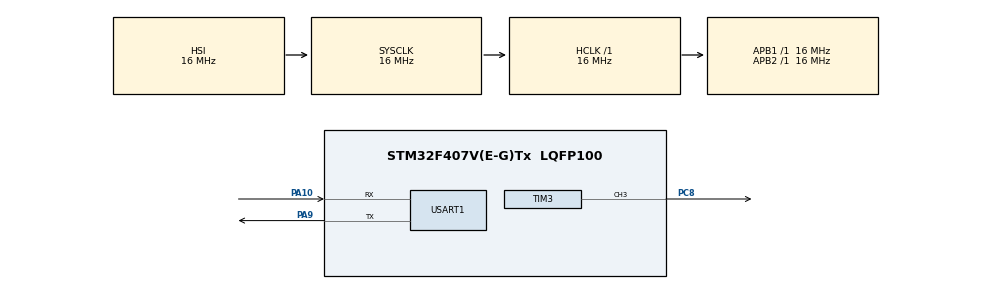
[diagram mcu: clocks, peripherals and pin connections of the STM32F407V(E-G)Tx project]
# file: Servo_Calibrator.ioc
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Mcu.Family=STM32F4
Mcu.Name=STM32F407V(E-G)Tx
Mcu.Package=LQFP100
NVIC.PriorityGroup=NVIC_PRIORITYGROUP_4
NVIC.USART1_IRQn=true\:0\:0\:false\:false\:true\:true\:true\:true
PA10.Mode=Asynchronous
PA10.Signal=USART1_RX
PA9.Mode=Asynchronous
PA9.Signal=USART1_TX
PC8.Signal=S_TIM3_CH3
ProjectManager.HeapSize=0x200
ProjectManager.StackSize=0x400
ProjectManager.TargetToolchain=STM32CubeIDE
RCC.AHBFreq_Value=16000000
RCC.APB1Freq_Value=16000000
RCC.APB2Freq_Value=16000000
RCC.CortexFreq_Value=16000000
RCC.HSE_VALUE=25000000
RCC.HSI_VALUE=16000000
RCC.LSE_VALUE=32768
RCC.SYSCLKFreq_VALUE=16000000
RCC.VCOOutputFreq_Value=192000000
SH.S_TIM3_CH3.0=TIM3_CH3,PWM Generation3 CH3
TIM3.Channel-PWM\ Generation3\ CH3=TIM_CHANNEL_3
TIM3.Period=19999
TIM3.Prescaler=15
USART1.VirtualMode=VM_ASYNC
board=custom

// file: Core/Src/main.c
/* USER CODE BEGIN Header */
/**
  ******************************************************************************
  * @file           : main.c
  * @brief          : Main program body
  ******************************************************************************
  * @attention
  *
  * Copyright (c) 2026 STMicroelectronics.
  * All rights reserved.
  *
  * This software is licensed under terms that can be found in the LICENSE file
  * in the root directory of this software component.
  * If no LICENSE file comes with this software, it is provided AS-IS.
  *
  ******************************************************************************
  */
/* USER CODE END Header */
#include "main.h"

TIM_HandleTypeDef htim3;

UART_HandleTypeDef huart1;

/* USER CODE BEGIN PV */
uint8_t rx_buffer[5];
/* USER CODE END PV */

void SystemClock_Config(void);
static void MX_GPIO_Init(void);
static void MX_TIM3_Init(void);
static void MX_USART1_UART_Init(void);

int main(void)
{

  /* MCU Configuration--------------------------------------------------------*/

  /* Reset of all peripherals, Initializes the Flash interface and the Systick. */
  HAL_Init();

  /* Configure the system clock */
  SystemClock_Config();

  /* Initialize all configured peripherals */
  MX_GPIO_Init();
  MX_TIM3_Init();
  MX_USART1_UART_Init();
  /* USER CODE BEGIN 2 */
  // Iniciar el PWM en el pin PC8
    HAL_TIM_PWM_Start(&htim3, TIM_CHANNEL_3);
    __HAL_TIM_SET_COMPARE(&htim3, TIM_CHANNEL_3, 1500); // Centro por defecto

    // Escuchar 5 bytes
    HAL_UART_Receive_IT(&huart1, rx_buffer, 5);
  /* USER CODE END 2 */

  /* Infinite loop */
  while (1)
  {

  }
}

void SystemClock_Config(void)
{
  RCC_OscInitTypeDef RCC_OscInitStruct = {0};
  RCC_ClkInitTypeDef RCC_ClkInitStruct = {0};

  /** Configure the main internal regulator output voltage
  */
  __HAL_RCC_PWR_CLK_ENABLE();
  __HAL_PWR_VOLTAGESCALING_CONFIG(PWR_REGULATOR_VOLTAGE_SCALE1);

  /** Initializes the RCC Oscillators according to the specified parameters
  * in the RCC_OscInitTypeDef structure.
  */
  RCC_OscInitStruct.OscillatorType = RCC_OSCILLATORTYPE_HSI;
  RCC_OscInitStruct.HSIState = RCC_HSI_ON;
  RCC_OscInitStruct.HSICalibrationValue = RCC_HSICALIBRATION_DEFAULT;
  RCC_OscInitStruct.PLL.PLLState = RCC_PLL_NONE;
  if (HAL_RCC_OscConfig(&RCC_OscInitStruct) != HAL_OK)
  {
    Error_Handler();
  }

  /** Initializes the CPU, AHB and APB buses clocks
  */
  RCC_ClkInitStruct.ClockType = RCC_CLOCKTYPE_HCLK|RCC_CLOCKTYPE_SYSCLK
                              |RCC_CLOCKTYPE_PCLK1|RCC_CLOCKTYPE_PCLK2;
  RCC_ClkInitStruct.SYSCLKSource = RCC_SYSCLKSOURCE_HSI;
  RCC_ClkInitStruct.AHBCLKDivider = RCC_SYSCLK_DIV1;
  RCC_ClkInitStruct.APB1CLKDivider = RCC_HCLK_DIV1;
  RCC_ClkInitStruct.APB2CLKDivider = RCC_HCLK_DIV1;

  if (HAL_RCC_ClockConfig(&RCC_ClkInitStruct, FLASH_LATENCY_0) != HAL_OK)
  {
    Error_Handler();
  }
}

static void MX_TIM3_Init(void)
{

  TIM_MasterConfigTypeDef sMasterConfig = {0};
  TIM_OC_InitTypeDef sConfigOC = {0};

  htim3.Instance = TIM3;
  htim3.Init.Prescaler = 15;
  htim3.Init.CounterMode = TIM_COUNTERMODE_UP;
  htim3.Init.Period = 19999;
  htim3.Init.ClockDivision = TIM_CLOCKDIVISION_DIV1;
  htim3.Init.AutoReloadPreload = TIM_AUTORELOAD_PRELOAD_DISABLE;
  if (HAL_TIM_PWM_Init(&htim3) != HAL_OK)
  {
    Error_Handler();
  }
  sMasterConfig.MasterOutputTrigger = TIM_TRGO_RESET;
  sMasterConfig.MasterSlaveMode = TIM_MASTERSLAVEMODE_DISABLE;
  if (HAL_TIMEx_MasterConfigSynchronization(&htim3, &sMasterConfig) != HAL_OK)
  {
    Error_Handler();
  }
  sConfigOC.OCMode = TIM_OCMODE_PWM1;
  sConfigOC.Pulse = 0;
  sConfigOC.OCPolarity = TIM_OCPOLARITY_HIGH;
  sConfigOC.OCFastMode = TIM_OCFAST_DISABLE;
  if (HAL_TIM_PWM_ConfigChannel(&htim3, &sConfigOC, TIM_CHANNEL_3) != HAL_OK)
  {
    Error_Handler();
  }
  HAL_TIM_MspPostInit(&htim3);

}

static void MX_USART1_UART_Init(void)
{

  huart1.Instance = USART1;
  huart1.Init.BaudRate = 115200;
  huart1.Init.WordLength = UART_WORDLENGTH_8B;
  huart1.Init.StopBits = UART_STOPBITS_1;
  huart1.Init.Parity = UART_PARITY_NONE;
  huart1.Init.Mode = UART_MODE_TX_RX;
  huart1.Init.HwFlowCtl = UART_HWCONTROL_NONE;
  huart1.Init.OverSampling = UART_OVERSAMPLING_16;
  if (HAL_UART_Init(&huart1) != HAL_OK)
  {
    Error_Handler();
  }

}

static void MX_GPIO_Init(void)
{

  /* GPIO Ports Clock Enable */
  __HAL_RCC_GPIOC_CLK_ENABLE();
  __HAL_RCC_GPIOA_CLK_ENABLE();

}

/* USER CODE BEGIN 4 */
void HAL_UART_RxCpltCallback(UART_HandleTypeDef *huart) {
    if (huart->Instance == USART1) {

        // Verificar Cabecera y Cola
        if (rx_buffer[0] == 0xAA && rx_buffer[1] == 0x55 && rx_buffer[4] == 0xFF) {

            // Reconstruir el valor de 16 bits (ej. 1500)
            uint16_t servo_val = (rx_buffer[2] << 8) | rx_buffer[3];

            // Protección de seguridad en el hardware (evitar que rompa algo si Python falla)
            if(servo_val >= 500 && servo_val <= 2500){
                __HAL_TIM_SET_COMPARE(&htim3, TIM_CHANNEL_3, servo_val);
            }
        }
        // Escuchar el siguiente comando
        rx_buffer[0] = 0;
        HAL_UART_Receive_IT(&huart1, rx_buffer, 5);
    }
}
/* USER CODE END 4 */

void Error_Handler(void)
{
  __disable_irq();
  while (1)
  {
  }
}
